# STM32WBA24 register map
File version: 0.2
CPU: CM33 r0p1, little endian, MPU, FPU, 4 interrupt priority bits
Registers are 32-bit, read-write, reset 0x0 unless marked. A register's access mark holds for its fields unless they carry their own. Offsets are from the block's base; [hi:lo] are bit positions.

## XSPI1 — XSPI1 register block
Base 0x420D1400
Same registers: SEC_XSPI1 0x520D1400
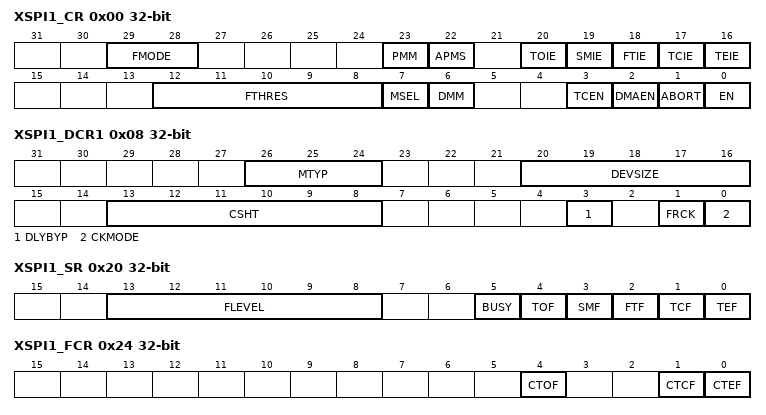
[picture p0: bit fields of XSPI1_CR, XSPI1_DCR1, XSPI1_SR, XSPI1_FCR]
0x00 XSPI1_CR — XSPI control register
  [29:28] FMODE — Functional mode
    0=Indirect-write mode; 1=Indirect-read mode; 2=No action derived from this setting; 3=Memory-mapped mode
  [23] PMM
  [22] APMS
  [20] TOIE — Timeout interrupt enable
    0=Interrupt disabled; 1=Interrupt enabled
  [19] SMIE
  [18] FTIE — FIFO threshold interrupt enable
    0=Interrupt disabled; 1=Interrupt enabled
  [17] TCIE — Transfer complete interrupt enable
    0=Interrupt disabled; 1=Interrupt enabled
  [16] TEIE — Transfer error interrupt enable
    0=Interrupt disabled; 1=Interrupt enabled
  [12:8] FTHRES — FIFO threshold level
    0=FTF is set if there are one or more free bytes available to be written to in the FIFO inindirect-write mode, or if there are one or more valid bytes can be read from the FIFO inindirect-read mode; 1=FTF is set if there are two or more free bytes available to be written to in the FIFO inindirect-write mode, or if there are two or more valid bytes can be read from the FIFO inindirect-read mode; 31=FTF is set if there are 32 free bytes available to be written to in the FIFO in indirect-write mode, or if there are 32 valid bytes can be read from the FIFO in indirect-read mode
  [7] MSEL — External memory select
    0=External memory 1 selected (data exchanged over IO[3:0]); 1=External memory 2 selected (data exchanged over IO[7:4])
  [6] DMM — Dual-memory configuration
    0=Dual-memory configuration disabled; 1=Dual-memory configuration enabled
  [3] TCEN — Timeout counter enable
    0=The timeout counter is disabled, and thus the chip-select (NCS) remains active indefinitely after an access in memory-mapped mode; 1=The timeout counter is enabled, and thus the chip-select is released in the memory-mapped mode after TIMEOUT[15:0] cycles of external device inactivity
  [2] DMAEN — DMA enable
    0=DMA disabled for indirect mode; 1=DMA enabled for indirect mode
  [1] ABORT — Abort request
    0=No abort requested; 1=Abort requested
  [0] EN — Enable
    0=XSPI disabled; 1=XSPI enabled
0x08 XSPI1_DCR1 — XSPI device configuration register 1
  [26:24] MTYP — Memory type
    0=Micron mode, D0/D1 ordering in DTR 8-data-bit mode; 1=Macronix mode, D1/D0 ordering in DTR 8-data-bit mode; 2=Standard mode; 3=Macronix RAM mode, D1/D0 ordering in DTR 8-data-bit mode
  [20:16] DEVSIZE — Device size
  [13:8] CSHT — Chip-select high time
    0=NCS stays high for at least 1 cycle between external device commands; 1=NCS stays high for at least 2 cycles between external device commands; 63=NCS stays high for at least 64 cycles between external device commands
  [3] DLYBYP — Delay block bypass
    0=The internal sampling clock (called feedback clock) or the DQS data strobe external signal is delayed by the delay block (for more details on this block, refer to the dedicated section of the reference manual as it is not part of the XSPI peripheral); 1=The delay block is bypassed, so the internal sampling clock or the DQS data strobe external signal is not affected by the delay block
  [1] FRCK — Free running clock
    0=CLK is not free running; 1=CLK is free running (always provided)
  [0] CKMODE — Clock mode 0/mode 3
    0=CLK must stay low while NCS is high (chip-select released); 1=CLK must stay high while NCS is high (chip-select released)
0x0C XSPI1_DCR2 — XSPI device configuration register 2
  [7:0] PRESCALER — Clock prescaler
    0=Fless thansub CLKless than/sub = Fless thansub KERNELless than/sub , kernel clock used directly as XSPI CLK (prescaler bypassed); 1=Fless thansub CLKless than/sub = Fless thansub KERNELless than/sub /2
0x20 XSPI1_SR ro — XSPI status register
  [13:8] FLEVEL — FIFO level
  [5] BUSY
  [4] TOF — Timeout flag
  [3] SMF
  [2] FTF — FIFO threshold flag
  [1] TCF — Transfer complete flag
  [0] TEF — Transfer error flag
0x24 XSPI1_FCR wo — XSPI flag clear register
  [4] CTOF — Clear timeout flag
  [1] CTCF — Clear transfer complete flag
  [0] CTEF — Clear transfer error flag
0x40 XSPI1_DLR — XSPI data length register
  [31:0] DL — Data length
0x48 XSPI1_AR — XSPI address register
  [31:0] ADDRESS
0x50 XSPI1_DR — XSPI data register
  [31:0] DATA
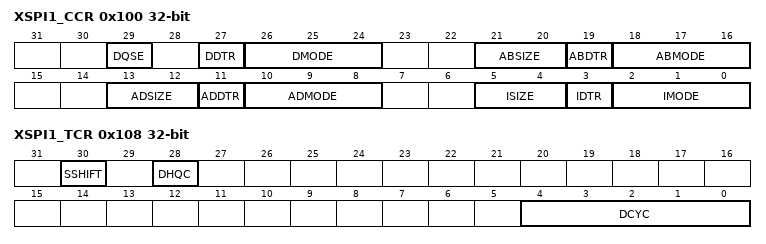
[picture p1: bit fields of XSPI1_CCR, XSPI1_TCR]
0x100 XSPI1_CCR — XSPI communication configuration register
  [29] DQSE — DQS enable
    0=DQS disabled; 1=DQS enabled
  [27] DDTR — Data double transfer rate
    0=DTR mode disabled for data phase; 1=DTR mode enabled for data phase
  [26:24] DMODE — Data mode
    0=No data; 1=Data on a single line; 2=Data on two lines; 3=Data on four lines; 4=Data on eight lines
  [21:20] ABSIZE — Alternate-byte size
    0=8-bit alternate bytes; 1=16-bit alternate bytes; 2=24-bit alternate bytes; 3=32-bit alternate bytes
  [19] ABDTR — Alternate- byte double transfer rate
    0=DTR mode disabled for the alternate-byte phase; 1=DTR mode enabled for the alternate-byte phase
  [18:16] ABMODE — Alternate-byte mode
    0=No alternate bytes; 1=Alternate bytes on a single line; 2=Alternate bytes on two lines; 3=Alternate bytes on four lines; 4=Alternate bytes on eight lines
  [13:12] ADSIZE — Address size
    0=8-bit address; 1=16-bit address; 2=24-bit address; 3=32-bit address
  [11] ADDTR — Address double transfer rate
    0=DTR mode disabled for the address phase; 1=DTR mode enabled for the address phase
  [10:8] ADMODE — Address mode
    0=No address; 1=Address on a single line; 2=Address on two lines; 3=Address on four lines; 4=Address on eight lines
  [5:4] ISIZE — Instruction size
    0=8-bit instruction; 1=16-bit instruction; 2=24-bit instruction; 3=32-bit instruction
  [3] IDTR — Instruction double transfer rate
    0=DTR mode disabled for the instruction phase; 1=DTR mode enabled for the instruction phase
  [2:0] IMODE — Instruction mode
    0=No instruction; 1=Instruction on a single line; 2=Instruction on two lines; 3=Instruction on four lines; 4=Instruction on eight lines
0x108 XSPI1_TCR — XSPI timing configuration register
  [30] SSHIFT — Sample shift
    0=No shift; 1=1/2 cycle shift
  [28] DHQC — Delay hold quarter cycle
    0=No delay hold; 1=1/4 cycle hold
  [4:0] DCYC — Number of dummy cycles
0x110 XSPI1_IR — XSPI instruction register
  [31:0] INSTRUCTION
0x120 XSPI1_ABR — XSPI alternate bytes register
  [31:0] ALTERNATE — Alternate bytes
0x130 XSPI1_LPTR — XSPI low-power timeout register
  [15:0] TIMEOUT — Timeout period
